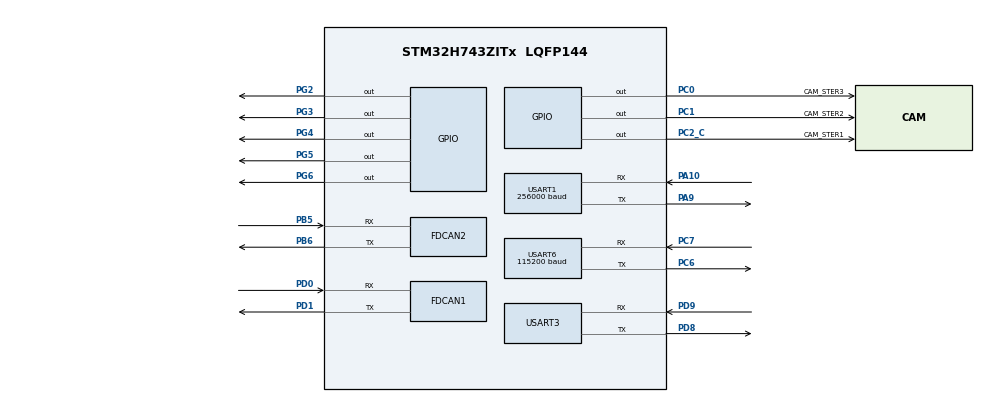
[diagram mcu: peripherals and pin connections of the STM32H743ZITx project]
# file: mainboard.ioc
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CORTEX_M7.default_mode_Activation=1
Dma.Request0=USART1_RX
Dma.Request1=USART1_TX
Dma.Request2=USART3_RX
Dma.Request3=USART3_TX
Dma.Request4=USART6_RX
Dma.Request5=USART6_TX
Dma.USART1_RX.0.Direction=DMA_PERIPH_TO_MEMORY
Dma.USART1_RX.0.EventEnable=DISABLE
Dma.USART1_RX.0.FIFOMode=DMA_FIFOMODE_ENABLE
Dma.USART1_RX.0.FIFOThreshold=DMA_FIFO_THRESHOLD_FULL
Dma.USART1_RX.0.Instance=DMA1_Stream0
Dma.USART1_RX.0.MemBurst=DMA_MBURST_SINGLE
Dma.USART1_RX.0.MemDataAlignment=DMA_MDATAALIGN_BYTE
Dma.USART1_RX.0.MemInc=DMA_MINC_ENABLE
Dma.USART1_RX.0.Mode=DMA_NORMAL
Dma.USART1_RX.0.PeriphBurst=DMA_PBURST_SINGLE
Dma.USART1_RX.0.PeriphDataAlignment=DMA_PDATAALIGN_BYTE
Dma.USART1_RX.0.PeriphInc=DMA_PINC_DISABLE
Dma.USART1_RX.0.Polarity=HAL_DMAMUX_REQ_GEN_RISING
Dma.USART1_RX.0.Priority=DMA_PRIORITY_LOW
Dma.USART1_RX.0.RequestNumber=1
Dma.USART1_RX.0.SignalID=NONE
Dma.USART1_RX.0.SyncEnable=DISABLE
Dma.USART1_RX.0.SyncPolarity=HAL_DMAMUX_SYNC_NO_EVENT
Dma.USART1_RX.0.SyncRequestNumber=1
Dma.USART1_RX.0.SyncSignalID=NONE
Dma.USART1_TX.1.Direction=DMA_MEMORY_TO_PERIPH
Dma.USART1_TX.1.EventEnable=DISABLE
Dma.USART1_TX.1.FIFOMode=DMA_FIFOMODE_ENABLE
Dma.USART1_TX.1.FIFOThreshold=DMA_FIFO_THRESHOLD_FULL
Dma.USART1_TX.1.Instance=DMA1_Stream1
Dma.USART1_TX.1.MemBurst=DMA_MBURST_SINGLE
Dma.USART1_TX.1.MemDataAlignment=DMA_MDATAALIGN_BYTE
Dma.USART1_TX.1.MemInc=DMA_MINC_ENABLE
Dma.USART1_TX.1.Mode=DMA_NORMAL
Dma.USART1_TX.1.PeriphBurst=DMA_PBURST_SINGLE
Dma.USART1_TX.1.PeriphDataAlignment=DMA_PDATAALIGN_BYTE
Dma.USART1_TX.1.PeriphInc=DMA_PINC_DISABLE
Dma.USART1_TX.1.Polarity=HAL_DMAMUX_REQ_GEN_RISING
Dma.USART1_TX.1.Priority=DMA_PRIORITY_LOW
Dma.USART1_TX.1.RequestNumber=1
Dma.USART1_TX.1.SignalID=NONE
Dma.USART1_TX.1.SyncEnable=DISABLE
Dma.USART1_TX.1.SyncPolarity=HAL_DMAMUX_SYNC_NO_EVENT
Dma.USART1_TX.1.SyncRequestNumber=1
Dma.USART1_TX.1.SyncSignalID=NONE
Dma.USART3_RX.2.Direction=DMA_PERIPH_TO_MEMORY
Dma.USART3_RX.2.EventEnable=DISABLE
Dma.USART3_RX.2.FIFOMode=DMA_FIFOMODE_ENABLE
Dma.USART3_RX.2.FIFOThreshold=DMA_FIFO_THRESHOLD_FULL
Dma.USART3_RX.2.Instance=DMA1_Stream2
Dma.USART3_RX.2.MemBurst=DMA_MBURST_SINGLE
Dma.USART3_RX.2.MemDataAlignment=DMA_MDATAALIGN_BYTE
Dma.USART3_RX.2.MemInc=DMA_MINC_ENABLE
Dma.USART3_RX.2.Mode=DMA_NORMAL
Dma.USART3_RX.2.PeriphBurst=DMA_PBURST_SINGLE
Dma.USART3_RX.2.PeriphDataAlignment=DMA_PDATAALIGN_BYTE
Dma.USART3_RX.2.PeriphInc=DMA_PINC_DISABLE
Dma.USART3_RX.2.Polarity=HAL_DMAMUX_REQ_GEN_RISING
Dma.USART3_RX.2.Priority=DMA_PRIORITY_LOW
Dma.USART3_RX.2.RequestNumber=1
Dma.USART3_RX.2.SignalID=NONE
Dma.USART3_RX.2.SyncEnable=DISABLE
Dma.USART3_RX.2.SyncPolarity=HAL_DMAMUX_SYNC_NO_EVENT
Dma.USART3_RX.2.SyncRequestNumber=1
Dma.USART3_RX.2.SyncSignalID=NONE
Dma.USART3_TX.3.Direction=DMA_MEMORY_TO_PERIPH
Dma.USART3_TX.3.EventEnable=DISABLE
Dma.USART3_TX.3.FIFOMode=DMA_FIFOMODE_ENABLE
Dma.USART3_TX.3.FIFOThreshold=DMA_FIFO_THRESHOLD_FULL
Dma.USART3_TX.3.Instance=DMA1_Stream3
Dma.USART3_TX.3.MemBurst=DMA_MBURST_SINGLE
Dma.USART3_TX.3.MemDataAlignment=DMA_MDATAALIGN_BYTE
Dma.USART3_TX.3.MemInc=DMA_MINC_ENABLE
Dma.USART3_TX.3.Mode=DMA_NORMAL
Dma.USART3_TX.3.PeriphBurst=DMA_PBURST_SINGLE
Dma.USART3_TX.3.PeriphDataAlignment=DMA_PDATAALIGN_BYTE
Dma.USART3_TX.3.PeriphInc=DMA_PINC_DISABLE
Dma.USART3_TX.3.Polarity=HAL_DMAMUX_REQ_GEN_RISING
Dma.USART3_TX.3.Priority=DMA_PRIORITY_LOW
Dma.USART3_TX.3.RequestNumber=1
Dma.USART3_TX.3.SignalID=NONE
Dma.USART3_TX.3.SyncEnable=DISABLE
Dma.USART3_TX.3.SyncPolarity=HAL_DMAMUX_SYNC_NO_EVENT
Dma.USART3_TX.3.SyncRequestNumber=1
Dma.USART3_TX.3.SyncSignalID=NONE
Dma.USART6_RX.4.Direction=DMA_PERIPH_TO_MEMORY
Dma.USART6_RX.4.EventEnable=DISABLE
Dma.USART6_RX.4.FIFOMode=DMA_FIFOMODE_ENABLE
Dma.USART6_RX.4.FIFOThreshold=DMA_FIFO_THRESHOLD_FULL
Dma.USART6_RX.4.Instance=DMA1_Stream4
Dma.USART6_RX.4.MemBurst=DMA_MBURST_SINGLE
Dma.USART6_RX.4.MemDataAlignment=DMA_MDATAALIGN_BYTE
Dma.USART6_RX.4.MemInc=DMA_MINC_ENABLE
Dma.USART6_RX.4.Mode=DMA_NORMAL
Dma.USART6_RX.4.PeriphBurst=DMA_PBURST_SINGLE
Dma.USART6_RX.4.PeriphDataAlignment=DMA_PDATAALIGN_BYTE
Dma.USART6_RX.4.PeriphInc=DMA_PINC_DISABLE
Dma.USART6_RX.4.Polarity=HAL_DMAMUX_REQ_GEN_RISING
Dma.USART6_RX.4.Priority=DMA_PRIORITY_LOW
Dma.USART6_RX.4.RequestNumber=1
Dma.USART6_RX.4.SignalID=NONE
Dma.USART6_RX.4.SyncEnable=DISABLE
Dma.USART6_RX.4.SyncPolarity=HAL_DMAMUX_SYNC_NO_EVENT
Dma.USART6_RX.4.SyncRequestNumber=1
Dma.USART6_RX.4.SyncSignalID=NONE
Dma.USART6_TX.5.Direction=DMA_MEMORY_TO_PERIPH
Dma.USART6_TX.5.EventEnable=DISABLE
Dma.USART6_TX.5.FIFOMode=DMA_FIFOMODE_ENABLE
Dma.USART6_TX.5.FIFOThreshold=DMA_FIFO_THRESHOLD_FULL
Dma.USART6_TX.5.Instance=DMA1_Stream5
Dma.USART6_TX.5.MemBurst=DMA_MBURST_SINGLE
Dma.USART6_TX.5.MemDataAlignment=DMA_MDATAALIGN_BYTE
Dma.USART6_TX.5.MemInc=DMA_MINC_ENABLE
Dma.USART6_TX.5.Mode=DMA_NORMAL
Dma.USART6_TX.5.PeriphBurst=DMA_PBURST_SINGLE
Dma.USART6_TX.5.PeriphDataAlignment=DMA_PDATAALIGN_BYTE
Dma.USART6_TX.5.PeriphInc=DMA_PINC_DISABLE
Dma.USART6_TX.5.Polarity=HAL_DMAMUX_REQ_GEN_RISING
Dma.USART6_TX.5.Priority=DMA_PRIORITY_LOW
Dma.USART6_TX.5.RequestNumber=1
Dma.USART6_TX.5.SignalID=NONE
Dma.USART6_TX.5.SyncEnable=DISABLE
Dma.USART6_TX.5.SyncPolarity=HAL_DMAMUX_SYNC_NO_EVENT
Dma.USART6_TX.5.SyncRequestNumber=1
Dma.USART6_TX.5.SyncSignalID=NONE
FDCAN1.AutoRetransmission=DISABLE
FDCAN1.CalculateBaudRateNominal=500000
FDCAN1.CalculateTimeBitNominal=2000
FDCAN1.CalculateTimeQuantumNominal=200.0
FDCAN1.DataPrescaler=24
FDCAN1.DataTimeSeg1=4
FDCAN1.DataTimeSeg2=5
FDCAN1.NominalPrescaler=24
FDCAN1.NominalTimeSeg1=4
FDCAN1.NominalTimeSeg2=5
FDCAN1.ProtocolException=ENABLE
FDCAN1.RxFifo0ElmtsNbr=1
FDCAN1.StdFiltersNbr=1
FDCAN1.TransmitPause=DISABLE
FDCAN1.TxBuffersNbr=1
FDCAN1.TxEventsNbr=1
FDCAN1.TxFifoQueueElmtsNbr=8
FDCAN1.TxFifoQueueMode=FDCAN_TX_FIFO_OPERATION
FDCAN2.AutoRetransmission=DISABLE
FDCAN2.CalculateBaudRateNominal=55555
FDCAN2.CalculateTimeBitNominal=18000
FDCAN2.CalculateTimeQuantumNominal=1000.0000000000001
FDCAN2.DataPrescaler=24
FDCAN2.DataSyncJumpWidth=1
FDCAN2.DataTimeSeg1=9
FDCAN2.DataTimeSeg2=8
FDCAN2.NominalPrescaler=120
FDCAN2.NominalSyncJumpWidth=1
FDCAN2.NominalTimeSeg1=9
FDCAN2.NominalTimeSeg2=8
FDCAN2.ProtocolException=ENABLE
FDCAN2.RxFifo0ElmtsNbr=1
FDCAN2.StdFiltersNbr=1
FDCAN2.TxBuffersNbr=1
FDCAN2.TxEventsNbr=1
FDCAN2.TxFifoQueueElmtsNbr=8
Mcu.Family=STM32H7
Mcu.Name=STM32H743ZITx
Mcu.Package=LQFP144
NVIC.DMA1_Stream0_IRQn=true\:0\:0\:false\:false\:true\:false\:true\:true
NVIC.DMA1_Stream1_IRQn=true\:0\:0\:false\:false\:true\:false\:true\:true
NVIC.DMA1_Stream2_IRQn=true\:0\:0\:false\:false\:true\:false\:true\:true
NVIC.DMA1_Stream3_IRQn=true\:0\:0\:false\:false\:true\:false\:true\:true
NVIC.DMA1_Stream4_IRQn=true\:0\:0\:false\:false\:true\:false\:true\:true
NVIC.DMA1_Stream5_IRQn=true\:0\:0\:false\:false\:true\:false\:true\:true
NVIC.FDCAN1_IT0_IRQn=true\:0\:0\:false\:false\:true\:true\:true\:true
NVIC.FDCAN1_IT1_IRQn=true\:0\:0\:false\:false\:true\:true\:true\:true
NVIC.FDCAN2_IT0_IRQn=true\:0\:0\:false\:false\:true\:true\:true\:true
NVIC.FDCAN2_IT1_IRQn=true\:0\:0\:false\:false\:true\:true\:true\:true
NVIC.PriorityGroup=NVIC_PRIORITYGROUP_4
NVIC.TIM4_IRQn=true\:0\:0\:false\:false\:true\:true\:true\:true
NVIC.TIM7_IRQn=true\:2\:0\:true\:false\:true\:true\:true\:true
NVIC.USART1_IRQn=true\:0\:0\:false\:false\:true\:true\:true\:true
NVIC.USART3_IRQn=true\:0\:0\:false\:false\:true\:true\:true\:true
NVIC.USART6_IRQn=true\:0\:0\:false\:false\:true\:true\:true\:true
PA10.Mode=Asynchronous
PA10.Signal=USART1_RX
PA9.Mode=Asynchronous
PA9.Signal=USART1_TX
PB5.Mode=FDCAN_Activate
PB5.Signal=FDCAN2_RX
PB6.Mode=FDCAN_Activate
PB6.Signal=FDCAN2_TX
PC0.GPIO_Label=CAM_STER3
PC0.Signal=GPIO_Output
PC1.GPIO_Label=CAM_STER2
PC1.Signal=GPIO_Output
PC2_C.GPIO_Label=CAM_STER1
PC2_C.Signal=GPIO_Output
PC6.Mode=Asynchronous
PC6.Signal=USART6_TX
PC7.Mode=Asynchronous
PC7.Signal=USART6_RX
PD0.Mode=FDCAN_Activate
PD0.Signal=FDCAN1_RX
PD1.Mode=FDCAN_Activate
PD1.Signal=FDCAN1_TX
PD8.Mode=Asynchronous
PD8.Signal=USART3_TX
PD9.Mode=Asynchronous
PD9.Signal=USART3_RX
PG2.Signal=GPIO_Output
PG3.Signal=GPIO_Output
PG4.Signal=GPIO_Output
PG5.Signal=GPIO_Output
PG6.Signal=GPIO_Output
PH0-OSC_IN\ (PH0).Mode=HSE-External-Oscillator
PH0-OSC_IN\ (PH0).Signal=RCC_OSC_IN
PH1-OSC_OUT\ (PH1).Mode=HSE-External-Oscillator
PH1-OSC_OUT\ (PH1).Signal=RCC_OSC_OUT
ProjectManager.HeapSize=0x200
ProjectManager.StackSize=0x400
ProjectManager.TargetToolchain=STM32CubeIDE
RCC.ADCFreq_Value=16125000
RCC.APB1Freq_Value=120000000
RCC.APB2Freq_Value=120000000
RCC.APB3Freq_Value=120000000
RCC.APB4Freq_Value=120000000
RCC.CortexFreq_Value=480000000
RCC.D1PPRE=RCC_APB3_DIV2
RCC.D2PPRE1=RCC_APB1_DIV2
RCC.D2PPRE2=RCC_APB2_DIV2
RCC.D3PPRE=RCC_APB4_DIV2
RCC.DIVM1=1
RCC.DIVN1=120
RCC.DIVQ1=8
RCC.HCLKFreq_Value=240000000
RCC.HPRE=RCC_HCLK_DIV2
RCC.HSE_VALUE=8000000
RCC.PLL2FRACN=0
RCC.PLL3FRACN=0
RCC.PLLFRACN=0
RCC.PLLSourceVirtual=RCC_PLLSOURCE_HSE
RCC.SYSCLKFreq_VALUE=480000000
RCC.SYSCLKSource=RCC_SYSCLKSOURCE_PLLCLK
RCC.USBFreq_Value=120000000
TIM4.Channel-Output\ Compare1\ No\ Output=TIM_CHANNEL_1
TIM4.Channel-Output\ Compare2\ No\ Output=TIM_CHANNEL_2
TIM4.Channel-Output\ Compare3\ No\ Output=TIM_CHANNEL_3
TIM4.Period=20000
TIM4.Prescaler=240
TIM4.Pulse-Output\ Compare1\ No\ Output=1500
TIM4.Pulse-Output\ Compare2\ No\ Output=1000
TIM4.Pulse-Output\ Compare3\ No\ Output=2000
TIM7.Period=49999
TIM7.Prescaler=479
USART1.BaudRate=256000
USART1.OverrunDisableParam=ADVFEATURE_OVERRUN_ENABLE
USART1.VirtualMode-Asynchronous=VM_ASYNC
USART3.VirtualMode-Asynchronous=VM_ASYNC
USART6.BaudRate=115200
USART6.VirtualMode-Asynchronous=VM_ASYNC
VP_IWDG1_VS_IWDG.Mode=IWDG_Activate
VP_MEMORYMAP_VS_MEMORYMAP.Mode=CurAppReg
VP_TIM4_VS_ClockSourceINT.Mode=Internal
VP_TIM4_VS_no_output1.Mode=Output Compare1 No Output
VP_TIM4_VS_no_output2.Mode=Output Compare2 No Output
VP_TIM4_VS_no_output3.Mode=Output Compare3 No Output
VP_TIM7_VS_ClockSourceINT.Mode=Enable_Timer
board=custom

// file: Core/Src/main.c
/* USER CODE BEGIN Header */
/**
  ******************************************************************************
  * @file           : main.c
  * @brief          : Main program body
  ******************************************************************************
  * @attention
  *
  * Copyright (c) 2025 STMicroelectronics.
  * All rights reserved.
  *
  * This software is licensed under terms that can be found in the LICENSE file
  * in the root directory of this software component.
  * If no LICENSE file comes with this software, it is provided AS-IS.
  *
  ******************************************************************************
  */
/* USER CODE END Header */
#include "main.h"

/* USER CODE BEGIN Includes */
#include "project_main.h"
/* USER CODE END Includes */

FDCAN_HandleTypeDef hfdcan1;
FDCAN_HandleTypeDef hfdcan2;

IWDG_HandleTypeDef hiwdg1;

TIM_HandleTypeDef htim4;
TIM_HandleTypeDef htim7;

UART_HandleTypeDef huart1;
UART_HandleTypeDef huart3;
UART_HandleTypeDef huart6;
DMA_HandleTypeDef hdma_usart1_rx;
DMA_HandleTypeDef hdma_usart1_tx;
DMA_HandleTypeDef hdma_usart3_rx;
DMA_HandleTypeDef hdma_usart3_tx;
DMA_HandleTypeDef hdma_usart6_rx;
DMA_HandleTypeDef hdma_usart6_tx;

void SystemClock_Config(void);
static void MPU_Config(void);
static void MX_GPIO_Init(void);
static void MX_DMA_Init(void);
static void MX_FDCAN1_Init(void);
static void MX_FDCAN2_Init(void);
static void MX_USART1_UART_Init(void);
static void MX_USART3_UART_Init(void);
static void MX_TIM4_Init(void);
static void MX_USART6_UART_Init(void);
static void MX_IWDG1_Init(void);
static void MX_TIM7_Init(void);

int main(void)
{

  /* MPU Configuration--------------------------------------------------------*/
  MPU_Config();

  /* MCU Configuration--------------------------------------------------------*/

  /* Reset of all peripherals, Initializes the Flash interface and the Systick. */
  HAL_Init();

  /* Configure the system clock */
  SystemClock_Config();

  /* Initialize all configured peripherals */
  MX_GPIO_Init();
  MX_DMA_Init();
  MX_FDCAN1_Init();
  MX_FDCAN2_Init();
  MX_USART1_UART_Init();
  MX_USART3_UART_Init();
  MX_TIM4_Init();
  MX_USART6_UART_Init();
  MX_IWDG1_Init();
  MX_TIM7_Init();
  /* USER CODE BEGIN 2 */

  project_main();

  /* USER CODE END 2 */

  /* Infinite loop */
  while (1)
  {

  }
}

void SystemClock_Config(void)
{
  RCC_OscInitTypeDef RCC_OscInitStruct = {0};
  RCC_ClkInitTypeDef RCC_ClkInitStruct = {0};

  /** Supply configuration update enable
  */
  HAL_PWREx_ConfigSupply(PWR_LDO_SUPPLY);

  /** Configure the main internal regulator output voltage
  */
  __HAL_PWR_VOLTAGESCALING_CONFIG(PWR_REGULATOR_VOLTAGE_SCALE0);

  while(!__HAL_PWR_GET_FLAG(PWR_FLAG_VOSRDY)) {}

  /** Initializes the RCC Oscillators according to the specified parameters
  * in the RCC_OscInitTypeDef structure.
  */
  RCC_OscInitStruct.OscillatorType = RCC_OSCILLATORTYPE_LSI|RCC_OSCILLATORTYPE_HSE;
  RCC_OscInitStruct.HSEState = RCC_HSE_ON;
  RCC_OscInitStruct.LSIState = RCC_LSI_ON;
  RCC_OscInitStruct.PLL.PLLState = RCC_PLL_ON;
  RCC_OscInitStruct.PLL.PLLSource = RCC_PLLSOURCE_HSE;
  RCC_OscInitStruct.PLL.PLLM = 1;
  RCC_OscInitStruct.PLL.PLLN = 120;
  RCC_OscInitStruct.PLL.PLLP = 2;
  RCC_OscInitStruct.PLL.PLLQ = 8;
  RCC_OscInitStruct.PLL.PLLR = 2;
  RCC_OscInitStruct.PLL.PLLRGE = RCC_PLL1VCIRANGE_3;
  RCC_OscInitStruct.PLL.PLLVCOSEL = RCC_PLL1VCOWIDE;
  RCC_OscInitStruct.PLL.PLLFRACN = 0;
  if (HAL_RCC_OscConfig(&RCC_OscInitStruct) != HAL_OK)
  {
    Error_Handler();
  }

  /** Initializes the CPU, AHB and APB buses clocks
  */
  RCC_ClkInitStruct.ClockType = RCC_CLOCKTYPE_HCLK|RCC_CLOCKTYPE_SYSCLK
                              |RCC_CLOCKTYPE_PCLK1|RCC_CLOCKTYPE_PCLK2
                              |RCC_CLOCKTYPE_D3PCLK1|RCC_CLOCKTYPE_D1PCLK1;
  RCC_ClkInitStruct.SYSCLKSource = RCC_SYSCLKSOURCE_PLLCLK;
  RCC_ClkInitStruct.SYSCLKDivider = RCC_SYSCLK_DIV1;
  RCC_ClkInitStruct.AHBCLKDivider = RCC_HCLK_DIV2;
  RCC_ClkInitStruct.APB3CLKDivider = RCC_APB3_DIV2;
  RCC_ClkInitStruct.APB1CLKDivider = RCC_APB1_DIV2;
  RCC_ClkInitStruct.APB2CLKDivider = RCC_APB2_DIV2;
  RCC_ClkInitStruct.APB4CLKDivider = RCC_APB4_DIV2;

  if (HAL_RCC_ClockConfig(&RCC_ClkInitStruct, FLASH_LATENCY_4) != HAL_OK)
  {
    Error_Handler();
  }
}

static void MX_FDCAN1_Init(void)
{

  hfdcan1.Instance = FDCAN1;
  hfdcan1.Init.FrameFormat = FDCAN_FRAME_CLASSIC;
  hfdcan1.Init.Mode = FDCAN_MODE_NORMAL;
  hfdcan1.Init.AutoRetransmission = DISABLE;
  hfdcan1.Init.TransmitPause = DISABLE;
  hfdcan1.Init.ProtocolException = ENABLE;
  hfdcan1.Init.NominalPrescaler = 24;
  hfdcan1.Init.NominalSyncJumpWidth = 1;
  hfdcan1.Init.NominalTimeSeg1 = 4;
  hfdcan1.Init.NominalTimeSeg2 = 5;
  hfdcan1.Init.DataPrescaler = 24;
  hfdcan1.Init.DataSyncJumpWidth = 1;
  hfdcan1.Init.DataTimeSeg1 = 4;
  hfdcan1.Init.DataTimeSeg2 = 5;
  hfdcan1.Init.MessageRAMOffset = 0;
  hfdcan1.Init.StdFiltersNbr = 1;
  hfdcan1.Init.ExtFiltersNbr = 0;
  hfdcan1.Init.RxFifo0ElmtsNbr = 1;
  hfdcan1.Init.RxFifo0ElmtSize = FDCAN_DATA_BYTES_8;
  hfdcan1.Init.RxFifo1ElmtsNbr = 0;
  hfdcan1.Init.RxFifo1ElmtSize = FDCAN_DATA_BYTES_8;
  hfdcan1.Init.RxBuffersNbr = 0;
  hfdcan1.Init.RxBufferSize = FDCAN_DATA_BYTES_8;
  hfdcan1.Init.TxEventsNbr = 1;
  hfdcan1.Init.TxBuffersNbr = 1;
  hfdcan1.Init.TxFifoQueueElmtsNbr = 8;
  hfdcan1.Init.TxFifoQueueMode = FDCAN_TX_FIFO_OPERATION;
  hfdcan1.Init.TxElmtSize = FDCAN_DATA_BYTES_8;
  if (HAL_FDCAN_Init(&hfdcan1) != HAL_OK)
  {
    Error_Handler();
  }

}

static void MX_FDCAN2_Init(void)
{

  hfdcan2.Instance = FDCAN2;
  hfdcan2.Init.FrameFormat = FDCAN_FRAME_CLASSIC;
  hfdcan2.Init.Mode = FDCAN_MODE_NORMAL;
  hfdcan2.Init.AutoRetransmission = DISABLE;
  hfdcan2.Init.TransmitPause = DISABLE;
  hfdcan2.Init.ProtocolException = ENABLE;
  hfdcan2.Init.NominalPrescaler = 120;
  hfdcan2.Init.NominalSyncJumpWidth = 1;
  hfdcan2.Init.NominalTimeSeg1 = 9;
  hfdcan2.Init.NominalTimeSeg2 = 8;
  hfdcan2.Init.DataPrescaler = 24;
  hfdcan2.Init.DataSyncJumpWidth = 1;
  hfdcan2.Init.DataTimeSeg1 = 9;
  hfdcan2.Init.DataTimeSeg2 = 8;
  hfdcan2.Init.MessageRAMOffset = 0;
  hfdcan2.Init.StdFiltersNbr = 1;
  hfdcan2.Init.ExtFiltersNbr = 0;
  hfdcan2.Init.RxFifo0ElmtsNbr = 1;
  hfdcan2.Init.RxFifo0ElmtSize = FDCAN_DATA_BYTES_8;
  hfdcan2.Init.RxFifo1ElmtsNbr = 0;
  hfdcan2.Init.RxFifo1ElmtSize = FDCAN_DATA_BYTES_8;
  hfdcan2.Init.RxBuffersNbr = 0;
  hfdcan2.Init.RxBufferSize = FDCAN_DATA_BYTES_8;
  hfdcan2.Init.TxEventsNbr = 1;
  hfdcan2.Init.TxBuffersNbr = 1;
  hfdcan2.Init.TxFifoQueueElmtsNbr = 8;
  hfdcan2.Init.TxFifoQueueMode = FDCAN_TX_FIFO_OPERATION;
  hfdcan2.Init.TxElmtSize = FDCAN_DATA_BYTES_8;
  if (HAL_FDCAN_Init(&hfdcan2) != HAL_OK)
  {
    Error_Handler();
  }

}

static void MX_IWDG1_Init(void)
{

  hiwdg1.Instance = IWDG1;
  hiwdg1.Init.Prescaler = IWDG_PRESCALER_4;
  hiwdg1.Init.Window = 4095;
  hiwdg1.Init.Reload = 4095;
  if (HAL_IWDG_Init(&hiwdg1) != HAL_OK)
  {
    Error_Handler();
  }

}

static void MX_TIM4_Init(void)
{

  TIM_ClockConfigTypeDef sClockSourceConfig = {0};
  TIM_MasterConfigTypeDef sMasterConfig = {0};
  TIM_OC_InitTypeDef sConfigOC = {0};

  htim4.Instance = TIM4;
  htim4.Init.Prescaler = 240;
  htim4.Init.CounterMode = TIM_COUNTERMODE_UP;
  htim4.Init.Period = 20000;
  htim4.Init.ClockDivision = TIM_CLOCKDIVISION_DIV1;
  htim4.Init.AutoReloadPreload = TIM_AUTORELOAD_PRELOAD_DISABLE;
  if (HAL_TIM_Base_Init(&htim4) != HAL_OK)
  {
    Error_Handler();
  }
  sClockSourceConfig.ClockSource = TIM_CLOCKSOURCE_INTERNAL;
  if (HAL_TIM_ConfigClockSource(&htim4, &sClockSourceConfig) != HAL_OK)
  {
    Error_Handler();
  }
  if (HAL_TIM_OC_Init(&htim4) != HAL_OK)
  {
    Error_Handler();
  }
  sMasterConfig.MasterOutputTrigger = TIM_TRGO_RESET;
  sMasterConfig.MasterSlaveMode = TIM_MASTERSLAVEMODE_DISABLE;
  if (HAL_TIMEx_MasterConfigSynchronization(&htim4, &sMasterConfig) != HAL_OK)
  {
    Error_Handler();
  }
  sConfigOC.OCMode = TIM_OCMODE_TIMING;
  sConfigOC.Pulse = 1500;
  sConfigOC.OCPolarity = TIM_OCPOLARITY_HIGH;
  sConfigOC.OCFastMode = TIM_OCFAST_DISABLE;
  if (HAL_TIM_OC_ConfigChannel(&htim4, &sConfigOC, TIM_CHANNEL_1) != HAL_OK)
  {
    Error_Handler();
  }
  sConfigOC.Pulse = 1000;
  if (HAL_TIM_OC_ConfigChannel(&htim4, &sConfigOC, TIM_CHANNEL_2) != HAL_OK)
  {
    Error_Handler();
  }
  sConfigOC.Pulse = 2000;
  if (HAL_TIM_OC_ConfigChannel(&htim4, &sConfigOC, TIM_CHANNEL_3) != HAL_OK)
  {
    Error_Handler();
  }

}

static void MX_TIM7_Init(void)
{

  TIM_MasterConfigTypeDef sMasterConfig = {0};

  htim7.Instance = TIM7;
  htim7.Init.Prescaler = 479;
  htim7.Init.CounterMode = TIM_COUNTERMODE_UP;
  htim7.Init.Period = 49999;
  htim7.Init.AutoReloadPreload = TIM_AUTORELOAD_PRELOAD_DISABLE;
  if (HAL_TIM_Base_Init(&htim7) != HAL_OK)
  {
    Error_Handler();
  }
  sMasterConfig.MasterOutputTrigger = TIM_TRGO_RESET;
  sMasterConfig.MasterSlaveMode = TIM_MASTERSLAVEMODE_DISABLE;
  if (HAL_TIMEx_MasterConfigSynchronization(&htim7, &sMasterConfig) != HAL_OK)
  {
    Error_Handler();
  }

}

static void MX_USART1_UART_Init(void)
{

  huart1.Instance = USART1;
  huart1.Init.BaudRate = 256000;
  huart1.Init.WordLength = UART_WORDLENGTH_8B;
  huart1.Init.StopBits = UART_STOPBITS_1;
  huart1.Init.Parity = UART_PARITY_NONE;
  huart1.Init.Mode = UART_MODE_TX_RX;
  huart1.Init.HwFlowCtl = UART_HWCONTROL_NONE;
  huart1.Init.OverSampling = UART_OVERSAMPLING_16;
  huart1.Init.OneBitSampling = UART_ONE_BIT_SAMPLE_DISABLE;
  huart1.Init.ClockPrescaler = UART_PRESCALER_DIV1;
  huart1.AdvancedInit.AdvFeatureInit = UART_ADVFEATURE_NO_INIT;
  if (HAL_UART_Init(&huart1) != HAL_OK)
  {
    Error_Handler();
  }
  if (HAL_UARTEx_SetTxFifoThreshold(&huart1, UART_TXFIFO_THRESHOLD_1_8) != HAL_OK)
  {
    Error_Handler();
  }
  if (HAL_UARTEx_SetRxFifoThreshold(&huart1, UART_RXFIFO_THRESHOLD_1_8) != HAL_OK)
  {
    Error_Handler();
  }
  if (HAL_UARTEx_DisableFifoMode(&huart1) != HAL_OK)
  {
    Error_Handler();
  }

}

static void MX_USART3_UART_Init(void)
{

  huart3.Instance = USART3;
  huart3.Init.BaudRate = 115200;
  huart3.Init.WordLength = UART_WORDLENGTH_8B;
  huart3.Init.StopBits = UART_STOPBITS_1;
  huart3.Init.Parity = UART_PARITY_NONE;
  huart3.Init.Mode = UART_MODE_TX_RX;
  huart3.Init.HwFlowCtl = UART_HWCONTROL_NONE;
  huart3.Init.OverSampling = UART_OVERSAMPLING_16;
  huart3.Init.OneBitSampling = UART_ONE_BIT_SAMPLE_DISABLE;
  huart3.Init.ClockPrescaler = UART_PRESCALER_DIV1;
  huart3.AdvancedInit.AdvFeatureInit = UART_ADVFEATURE_NO_INIT;
  if (HAL_UART_Init(&huart3) != HAL_OK)
  {
    Error_Handler();
  }
  if (HAL_UARTEx_SetTxFifoThreshold(&huart3, UART_TXFIFO_THRESHOLD_1_8) != HAL_OK)
  {
    Error_Handler();
  }
  if (HAL_UARTEx_SetRxFifoThreshold(&huart3, UART_RXFIFO_THRESHOLD_1_8) != HAL_OK)
  {
    Error_Handler();
  }
  if (HAL_UARTEx_DisableFifoMode(&huart3) != HAL_OK)
  {
    Error_Handler();
  }

}

static void MX_USART6_UART_Init(void)
{

  huart6.Instance = USART6;
  huart6.Init.BaudRate = 115200;
  huart6.Init.WordLength = UART_WORDLENGTH_8B;
  huart6.Init.StopBits = UART_STOPBITS_1;
  huart6.Init.Parity = UART_PARITY_NONE;
  huart6.Init.Mode = UART_MODE_TX_RX;
  huart6.Init.HwFlowCtl = UART_HWCONTROL_NONE;
  huart6.Init.OverSampling = UART_OVERSAMPLING_16;
  huart6.Init.OneBitSampling = UART_ONE_BIT_SAMPLE_DISABLE;
  huart6.Init.ClockPrescaler = UART_PRESCALER_DIV1;
  huart6.AdvancedInit.AdvFeatureInit = UART_ADVFEATURE_NO_INIT;
  if (HAL_UART_Init(&huart6) != HAL_OK)
  {
    Error_Handler();
  }
  if (HAL_UARTEx_SetTxFifoThreshold(&huart6, UART_TXFIFO_THRESHOLD_1_8) != HAL_OK)
  {
    Error_Handler();
  }
  if (HAL_UARTEx_SetRxFifoThreshold(&huart6, UART_RXFIFO_THRESHOLD_1_8) != HAL_OK)
  {
    Error_Handler();
  }
  if (HAL_UARTEx_DisableFifoMode(&huart6) != HAL_OK)
  {
    Error_Handler();
  }

}

static void MX_DMA_Init(void)
{

  /* DMA controller clock enable */
  __HAL_RCC_DMA1_CLK_ENABLE();

  /* DMA interrupt init */
  /* DMA1_Stream0_IRQn interrupt configuration */
  HAL_NVIC_SetPriority(DMA1_Stream0_IRQn, 0, 0);
  HAL_NVIC_EnableIRQ(DMA1_Stream0_IRQn);
  /* DMA1_Stream1_IRQn interrupt configuration */
  HAL_NVIC_SetPriority(DMA1_Stream1_IRQn, 0, 0);
  HAL_NVIC_EnableIRQ(DMA1_Stream1_IRQn);
  /* DMA1_Stream2_IRQn interrupt configuration */
  HAL_NVIC_SetPriority(DMA1_Stream2_IRQn, 0, 0);
  HAL_NVIC_EnableIRQ(DMA1_Stream2_IRQn);
  /* DMA1_Stream3_IRQn interrupt configuration */
  HAL_NVIC_SetPriority(DMA1_Stream3_IRQn, 0, 0);
  HAL_NVIC_EnableIRQ(DMA1_Stream3_IRQn);
  /* DMA1_Stream4_IRQn interrupt configuration */
  HAL_NVIC_SetPriority(DMA1_Stream4_IRQn, 0, 0);
  HAL_NVIC_EnableIRQ(DMA1_Stream4_IRQn);
  /* DMA1_Stream5_IRQn interrupt configuration */
  HAL_NVIC_SetPriority(DMA1_Stream5_IRQn, 0, 0);
  HAL_NVIC_EnableIRQ(DMA1_Stream5_IRQn);

}

static void MX_GPIO_Init(void)
{
  GPIO_InitTypeDef GPIO_InitStruct = {0};

  /* GPIO Ports Clock Enable */
  __HAL_RCC_GPIOH_CLK_ENABLE();
  __HAL_RCC_GPIOC_CLK_ENABLE();
  __HAL_RCC_GPIOD_CLK_ENABLE();
  __HAL_RCC_GPIOG_CLK_ENABLE();
  __HAL_RCC_GPIOA_CLK_ENABLE();
  __HAL_RCC_GPIOB_CLK_ENABLE();

  /*Configure GPIO pin Output Level */
  HAL_GPIO_WritePin(GPIOC, CAM_STER3_Pin|CAM_STER2_Pin|CAM_STER1_Pin, GPIO_PIN_RESET);

  /*Configure GPIO pin Output Level */
  HAL_GPIO_WritePin(GPIOG, GPIO_PIN_2|GPIO_PIN_3|GPIO_PIN_4|GPIO_PIN_5
                          |GPIO_PIN_6, GPIO_PIN_RESET);

  /*Configure GPIO pins : CAM_STER3_Pin CAM_STER2_Pin CAM_STER1_Pin */
  GPIO_InitStruct.Pin = CAM_STER3_Pin|CAM_STER2_Pin|CAM_STER1_Pin;
  GPIO_InitStruct.Mode = GPIO_MODE_OUTPUT_PP;
  GPIO_InitStruct.Pull = GPIO_NOPULL;
  GPIO_InitStruct.Speed = GPIO_SPEED_FREQ_LOW;
  HAL_GPIO_Init(GPIOC, &GPIO_InitStruct);

  /*Configure GPIO pins : PG2 PG3 PG4 PG5
                           PG6 */
  GPIO_InitStruct.Pin = GPIO_PIN_2|GPIO_PIN_3|GPIO_PIN_4|GPIO_PIN_5
                          |GPIO_PIN_6;
  GPIO_InitStruct.Mode = GPIO_MODE_OUTPUT_PP;
  GPIO_InitStruct.Pull = GPIO_NOPULL;
  GPIO_InitStruct.Speed = GPIO_SPEED_FREQ_LOW;
  HAL_GPIO_Init(GPIOG, &GPIO_InitStruct);

  /*AnalogSwitch Config */
  HAL_SYSCFG_AnalogSwitchConfig(SYSCFG_SWITCH_PC2, SYSCFG_SWITCH_PC2_CLOSE);

}

 /* MPU Configuration */

void MPU_Config(void)
{
  MPU_Region_InitTypeDef MPU_InitStruct = {0};

  /* Disables the MPU */
  HAL_MPU_Disable();

  /** Initializes and configures the Region and the memory to be protected
  */
  MPU_InitStruct.Enable = MPU_REGION_ENABLE;
  MPU_InitStruct.Number = MPU_REGION_NUMBER0;
  MPU_InitStruct.BaseAddress = 0x0;
  MPU_InitStruct.Size = MPU_REGION_SIZE_4GB;
  MPU_InitStruct.SubRegionDisable = 0x87;
  MPU_InitStruct.TypeExtField = MPU_TEX_LEVEL0;
  MPU_InitStruct.AccessPermission = MPU_REGION_NO_ACCESS;
  MPU_InitStruct.DisableExec = MPU_INSTRUCTION_ACCESS_DISABLE;
  MPU_InitStruct.IsShareable = MPU_ACCESS_SHAREABLE;
  MPU_InitStruct.IsCacheable = MPU_ACCESS_NOT_CACHEABLE;
  MPU_InitStruct.IsBufferable = MPU_ACCESS_NOT_BUFFERABLE;

  HAL_MPU_ConfigRegion(&MPU_InitStruct);
  /* Enables the MPU */
  HAL_MPU_Enable(MPU_PRIVILEGED_DEFAULT);

}

void Error_Handler(void)
{
  __disable_irq();
  while (1)
  {
  }
}
